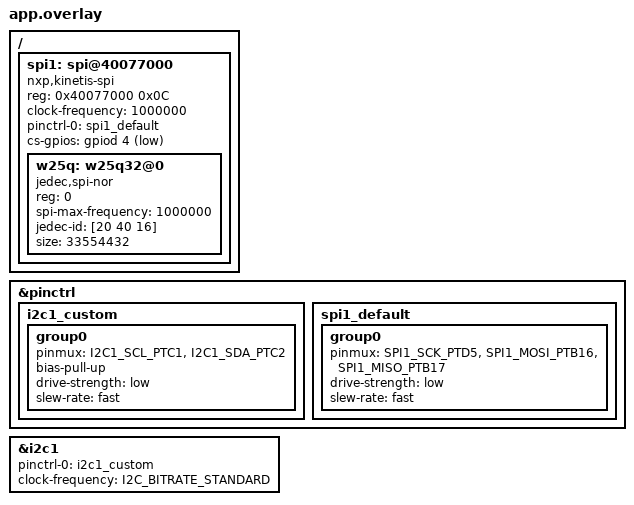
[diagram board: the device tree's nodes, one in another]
/*
 * IoT Monitor - Device Tree overlay
 * I2C1: PTC1(SCL, header A5) PTC2(SDA, header A4)
 * SPI1: PTD5(SCK) PTB16(MOSI) PTB17(MISO) PTD4(CS-GPIO)
 *
 * Nota: se usa I2C1 en PTC1/PTC2 — los pines I2C designados por NXP en el
 * header de esta placa — y no I2C0 en PTB2/PTB3 como en la version original.
 * Ver docs/adr/ADR-003-bus-i2c-sensores.md para el bring-up que motivo el
 * cambio.
 */

#include <nxp/kinetis/K32L2B31VLH0A-pinctrl.h>

&pinctrl {
    i2c1_custom: i2c1_custom {
        group0 {
            /* PTC1 = SCL (A5), PTC2 = SDA (A4), ALT2 para I2C1 */
            pinmux = <I2C1_SCL_PTC1>,
                     <I2C1_SDA_PTC2>;
            bias-pull-up;
            drive-strength = "low";
            slew-rate = "fast";
        };
    };

    spi1_default: spi1_default {
        group0 {
            /* PTD5 SCK, PTB16 MOSI, PTB17 MISO — ALT2. PTD4 (CS) se
             * maneja aparte como GPIO manual, no como función SPI. */
            pinmux = <SPI1_SCK_PTD5>,
                     <SPI1_MOSI_PTB16>,
                     <SPI1_MISO_PTB17>;
            drive-strength = "low";
            slew-rate = "fast";
        };
    };
};

&i2c1 {
    status = "okay";
    pinctrl-0 = <&i2c1_custom>;
    pinctrl-names = "default";
    clock-frequency = <I2C_BITRATE_STANDARD>;
};

/ {
    spi1: spi@40077000 {
        compatible = "nxp,kinetis-spi";
        reg = <0x40077000 0x0C>;
        #address-cells = <1>;
        #size-cells = <0>;
        clock-frequency = <1000000>;
        status = "okay";
        pinctrl-0 = <&spi1_default>;
        pinctrl-names = "default";
        cs-gpios = <&gpiod 4 GPIO_ACTIVE_LOW>;

        w25q: w25q32@0 {
            compatible = "jedec,spi-nor";
            reg = <0>;
            spi-max-frequency = <1000000>;
            jedec-id = [20 40 16];
            size = <33554432>;
            status = "okay";
        };
    };
};
